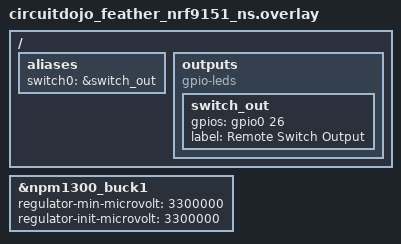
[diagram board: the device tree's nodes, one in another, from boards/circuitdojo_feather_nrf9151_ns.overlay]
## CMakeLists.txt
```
# SPDX-License-Identifier: MIT

cmake_minimum_required(VERSION 3.21.0)

# Merge the git-ignored remote-control key (README "Setup") into the
# application configuration when present. Zephyr combines this with the
# sysbuild-provided EXTRA_CONF_FILE (sysbuild/remote_switch.conf).
# CONFIGURE_DEPENDS makes Ninja re-run CMake if the key file is created or
# deleted after an initial build.
set(REMOTE_SWITCH_LOCAL_CONF ${CMAKE_CURRENT_LIST_DIR}/remote_switch.local.conf)
file(GLOB REMOTE_SWITCH_LOCAL_CONF_MATCH CONFIGURE_DEPENDS "${REMOTE_SWITCH_LOCAL_CONF}")
if(REMOTE_SWITCH_LOCAL_CONF_MATCH)
  message(STATUS "remote_switch: using ${REMOTE_SWITCH_LOCAL_CONF}")
  list(APPEND EXTRA_CONF_FILE ${REMOTE_SWITCH_LOCAL_CONF})
else()
  message(WARNING "remote_switch: ${REMOTE_SWITCH_LOCAL_CONF} not found; "
                  "remote control will be disabled (see README \"Setup\")")
endif()

find_package(Zephyr REQUIRED HINTS $ENV{ZEPHYR_BASE})
project(remote_switch)

rust_cargo_application()
target_sources(app PRIVATE src/board_io.c src/cellular.c)
target_sources_ifdef(CONFIG_REMOTE_SWITCH_DEBUG_SHELL app PRIVATE src/remote_shell.c)
set_source_files_properties(
  src/board_io.c
  src/cellular.c
  src/remote_shell.c
  PROPERTIES COMPILE_OPTIONS "-Wall;-Wextra;-Wmissing-prototypes"
)
```

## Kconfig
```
# SPDX-License-Identifier: MIT

menu "Remote switch"

config REMOTE_SWITCH_KEY
	string "Remote command key (64 hex digits)"
	default ""
	help
	  32-byte pre-shared key, hex encoded, used to authenticate remote
	  commands and replies with HMAC-SHA256. An empty or malformed value
	  disables remote control (commands are dropped).

	  Never commit a real key. Generate one into the git-ignored file
	  `remote_switch.local.conf` with
	  `tools/rsctl.py keygen -o remote_switch.local.conf`; CMakeLists.txt
	  merges that file into the build automatically when it exists.

config REMOTE_SWITCH_CELLULAR
	bool "Remote control over cellular (LTE-M / NB-IoT)"
	default y
	depends on NRF_MODEM_LIB && LTE_LINK_CONTROL && LTE_LC_PDN_MODULE && NET_SOCKETS
	help
	  Attach to the cellular network and accept authenticated commands on a
	  UDP port. The device sends nothing while idle and one small reply per
	  authenticated command.

if REMOTE_SWITCH_CELLULAR

config REMOTE_SWITCH_UDP_PORT
	int "UDP port for remote commands"
	default 4242
	range 1 65535

config REMOTE_SWITCH_CELLULAR_STACK_SIZE
	int "Cellular thread stack size"
	default 4096

config REMOTE_SWITCH_PDN_RECOVERY_TIMEOUT
	int "Seconds without a PDN connection before forcing a re-attach"
	default 300
	range 60 86400

config REMOTE_SWITCH_CELLULAR_WATCHDOG_TIMEOUT
	int "Seconds without cellular thread progress before withholding watchdog feed"
	default 900
	range 180 3600
	depends on REMOTE_SWITCH_WATCHDOG
	help
	  Maximum interval the cellular transport thread may go without
	  recording loop progress before `switch_controller` stops feeding the
	  hardware watchdog and allows `watchdog0` to reset the SoC. Generous
	  enough to span initial modem setup and fault recovery while ensuring a
	  hung modem IPC, AT command, or socket operation cannot leave remote
	  control permanently dead.

endif # REMOTE_SWITCH_CELLULAR

config REMOTE_SWITCH_WATCHDOG
	bool "Hardware watchdog supervision from switch_controller"
	default y
	depends on WATCHDOG
	help
	  Arm the SoC hardware watchdog (`aliases::watchdog0`) and feed it from
	  the async `switch_controller` executor task (gated on cellular thread
	  liveness when enabled) so an I2C bus hang, hung modem IPC, or
	  scheduler livelock resets the SoC and returns `switch0` to OFF.

if REMOTE_SWITCH_WATCHDOG

config REMOTE_SWITCH_WATCHDOG_TIMEOUT_MS
	int "Hardware watchdog timeout in milliseconds"
	default 30000
	range 3000 600000
	help
	  SoC reset timeout for `watchdog0`. A kernel timer wakes
	  `switch_controller` every one-third of this interval to feed the
	  watchdog while idle.

endif # REMOTE_SWITCH_WATCHDOG

config REMOTE_SWITCH_DEBUG_SHELL
	bool "Debug shell on console UART (`rs msg` and raw `at` commands)"
	default n
	select SHELL
	imply AT_SHELL
	help
	  Enable the interactive UART shell with the authenticated `rs msg`
	  command and raw `at` modem access. Disabled by default so production
	  builds do not expose unauthenticated UART/AT commands or spend flash
	  and RAM on the shell subsystem. Enable for bench testing via
	  `CONFIG_REMOTE_SWITCH_DEBUG_SHELL=y` in `remote_switch.local.conf` or
	  `-Dremote_switch_CONFIG_REMOTE_SWITCH_DEBUG_SHELL=y`.

endmenu

if REMOTE_SWITCH_DEBUG_SHELL

configdefault SHELL_STACK_SIZE
	default 4096

configdefault SHELL_WILDCARD
	default n

configdefault LTE_SHELL
	default n

endif # REMOTE_SWITCH_DEBUG_SHELL

source "Kconfig.zephyr"
```

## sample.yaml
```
# SPDX-License-Identifier: MIT
---
# Note: `circuitdojo_feather_nrf9151/nrf9151/ns` is built directly via
# `west build -b circuitdojo_feather_nrf9151/nrf9151/ns --sysbuild`; upstream
# `nfed` carries a legacy HWMv1 identifier (`circuitdojo_feather_nrf9151_ns`) in
# `circuitdojo_feather_nrf9151_nrf9151_ns.yaml` that Twister skips during board
# discovery, so Twister CI validates the nRF9151 Non-Secure + TF-M + MCUboot +
# modem sysbuild flow on `nrf9151dk/nrf9151/ns`. Secure-only targets are not
# listed because the nRF91 modem library requires the non-secure build.
sample:
  name: Remote Switch
  description: Rust on Zephyr cellular remote switch controller for nRF9151 Feather
common:
  sysbuild: true
  build_only: true
  filter: CONFIG_RUST_SUPPORTED
  platform_allow:
    - nrf9151dk/nrf9151/ns
  integration_platforms:
    - nrf9151dk/nrf9151/ns
  tags:
    - gpio
    - input
    - lte
    - mcuboot
    - rust
tests:
  sample.remote_switch.build: {}
  sample.remote_switch.debug_shell:
    extra_configs:
      - CONFIG_REMOTE_SWITCH_DEBUG_SHELL=y
```

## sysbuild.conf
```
# SPDX-License-Identifier: MIT

# SECURITY NOTE: By default, MCUboot signs images with its built-in development
# key (`root-ec-p256.pem`), which is public and NOT secure for production.
# For production deployments, generate an offline ECDSA-P256 keypair, keep the
# private key outside version control, and pass:
#   -DSB_CONFIG_BOOT_SIGNATURE_KEY_FILE=\"/secure/path/to/prod-key.pem\"
SB_CONFIG_BOOTLOADER_MCUBOOT=y
```

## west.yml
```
# SPDX-License-Identifier: MIT
---
manifest:
  remotes:
    - name: circuitdojo
      url-base: https://github.com/circuitdojo
    - name: zephyrproject-rtos
      url-base: https://github.com/zephyrproject-rtos

  projects:
    - name: nfed
      remote: circuitdojo
      repo-path: nrf9160-feather-examples-and-drivers.git
      path: nfed
      # Pinned commit on branch v3.4.x for reproducible builds
      revision: 79ee909971558cbea852dd668134be6ef73adfe7
      import: true
    - name: zephyr-lang-rust
      remote: zephyrproject-rtos
      repo-path: zephyr-lang-rust.git
      path: modules/lang/rust
      revision: 6823b690ed2daf636323cbb8a10447d142752e1f

  self:
    path: remote_switch
```

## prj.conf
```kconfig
# SPDX-License-Identifier: MIT

# GPIO + debounced button input subsystem
CONFIG_GPIO=y
CONFIG_INPUT=y
CONFIG_INPUT_THREAD_STACK_SIZE=2048

# Console logging
CONFIG_LOG=y
CONFIG_LOG_PRINTK=y

# Reset rather than halting with outputs latched if a fatal fault/panic occurs,
# and supervise liveness with the hardware watchdog (`aliases::watchdog0`)
CONFIG_RESET_ON_FATAL_ERROR=y
CONFIG_WATCHDOG=y

# Rust support + Embassy executor integration
CONFIG_RUST=y
CONFIG_MAIN_STACK_SIZE=4096

# Cellular modem, LTE link control, and offloaded sockets
CONFIG_NETWORKING=y
CONFIG_NET_NATIVE=n
CONFIG_NET_SOCKETS=y
CONFIG_NET_SOCKETS_OFFLOAD=y
CONFIG_NRF_MODEM_LIB=y
CONFIG_NRF_MODEM_LIB_ON_FAULT_APPLICATION_SPECIFIC=y
CONFIG_LTE_LINK_CONTROL=y
CONFIG_LTE_LC_PDN_MODULE=y
CONFIG_LTE_NETWORK_MODE_LTE_M_NBIOT=y
CONFIG_LTE_MODE_PREFERENCE_LTE_M=y

# Default PDN: 1NCE APN (change it for other SIM providers), IPv4 only so the
# network never sends IPv6 router advertisements that would count as data.
CONFIG_LTE_LC_PDN_DEFAULTS_OVERRIDE=y
CONFIG_LTE_LC_PDN_DEFAULT_APN="iot.1nce.net"
CONFIG_LTE_LC_PDN_DEFAULT_FAM_IPV4=y
CONFIG_NET_IPV6=n

# No background traffic: the app uses no DNS, NTP, or cloud services
CONFIG_LTE_LC_DNS_FALLBACK_MODULE=n

# Remote-command replay counter persisted with settings on NVS (storage_partition)
CONFIG_FLASH=y
CONFIG_FLASH_MAP=y
CONFIG_NVS=y
CONFIG_SETTINGS=y
CONFIG_SETTINGS_NVS=y

# Note: The UART debug shell (`rs msg ...` and `at ...`) is disabled by default
# for production safety and flash/RAM savings. Enable it for local bench testing
# with `CONFIG_REMOTE_SWITCH_DEBUG_SHELL=y` in `remote_switch.local.conf` or on
# the `west build` command line.
```

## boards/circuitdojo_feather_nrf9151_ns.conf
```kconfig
# SPDX-License-Identifier: MIT

# I2C + nPM1300 PMIC LED and regulator drivers (status LED + 3.3 V VDDIO on BUCK1)
CONFIG_I2C=y
CONFIG_LED=y
CONFIG_LED_NPM13XX=y
CONFIG_REGULATOR=y
CONFIG_REGULATOR_NPM13XX=y

# Disable generic gpio-leds driver so Zephyr does not contend with Rust GpioPin
# ownership of the switch0 output node (compatible = "gpio-leds" in overlay)
CONFIG_LED_GPIO=n

# Prevent TF-M UART1 from conflicting with I2C and cluttering serial logs
CONFIG_TFM_SECURE_UART=n
CONFIG_TFM_LOG_LEVEL_SILENCE=y
```

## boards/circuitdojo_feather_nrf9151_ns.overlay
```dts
/* SPDX-License-Identifier: MIT */

/*
 * Devicetree overlay for Circuit Dojo nRF9151 Feather (non-secure).
 *
 * - Default switch output is mapped to Feather header pin D2 (P0.26), active-high.
 *   Update `&gpio0 26` (and polarity if needed) to match your relay or MOSFET
 *   driver circuit, or supply a local `*.local.overlay` via `-DDTC_OVERLAY_FILE`.
 * - nPM1300 BUCK1 (`VDDIO` / `3V3`) defaults to 2.7 V via hardware VSET resistors;
 *   `&npm1300_buck1` is configured to 3.3 V so GPIO outputs drive 3.3 V logic.
 *
 * Note: `compatible = "gpio-leds"` provides the `gpios` binding for the
 * `switch0` alias (detected via `cfg!(dt = "aliases::switch0")` in Rust and
 * `GPIO_DT_SPEC_GET(DT_ALIAS(switch0), gpios)` in `src/board_io.c`), while
 * `CONFIG_LED_GPIO=n` in `boards/circuitdojo_feather_nrf9151_ns.conf` prevents
 * Zephyr's C `led_gpio` driver from claiming the same pin.
 *
 * Hardware fail-safe note: SoC GPIOs are high-impedance (floating) during
 * power-on reset, MCUboot execution, TF-M startup, and early kernel boot until
 * `board_switch_early_init` (`POST_KERNEL`) configures `switch0` as an
 * inactive output. Fit an external pull-down resistor (e.g., 10 kOhm to GND
 * for active-high drivers, or pull-up to VDD for active-low drivers) on the
 * relay/MOSFET gate so the load cannot glitch ON before firmware
 * initialization completes.
 */

/ {
	aliases {
		switch0 = &switch_out;
	};

	outputs {
		compatible = "gpio-leds";
		switch_out: switch_out {
			gpios = <&gpio0 26 GPIO_ACTIVE_HIGH>;
			label = "Remote Switch Output";
		};
	};
};

&npm1300_buck1 {
	regulator-min-microvolt = <3300000>;
	regulator-init-microvolt = <3300000>;
};
```

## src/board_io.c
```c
// SPDX-License-Identifier: MIT
/*
 * Thin C bridge for Zephyr/Nordic subsystems not yet wrapped in (or whose error
 * codes are discarded by) zephyr-lang-rust:
 *   1. Checked `aliases::switch0` GPIO output with early POST_KERNEL safe OFF.
 *   2. Onboard nPM1300 status LED (channel 2, host-controlled blue LED).
 *   3. Debounced button events via Zephyr's gpio-keys input subsystem.
 *   4. Hardware watchdog (`aliases::watchdog0`) + periodic tick timer.
 *   5. MCUboot runtime image confirmation after safe application startup.
 *   6. Flash persistence of the remote-command replay counter (settings/NVS).
 */

#include "board_io.h"

#include <errno.h>
#include <stdbool.h>
#include <stdint.h>

#include <zephyr/device.h>
#include <zephyr/devicetree.h>
#include <zephyr/init.h>
#include <zephyr/kernel.h>
#include <zephyr/logging/log.h>
#include <zephyr/sys/util.h>

#if IS_ENABLED(CONFIG_GPIO)
#include <zephyr/drivers/gpio.h>
#endif

#if IS_ENABLED(CONFIG_LED)
#include <zephyr/drivers/led.h>
#endif

#if IS_ENABLED(CONFIG_INPUT)
#include <zephyr/input/input.h>
#endif

#if IS_ENABLED(CONFIG_MCUBOOT_IMG_MANAGER)
#include <zephyr/dfu/mcuboot.h>
#endif

#if IS_ENABLED(CONFIG_REMOTE_SWITCH_WATCHDOG)
#include <zephyr/drivers/watchdog.h>
#endif

#if IS_ENABLED(CONFIG_SETTINGS)
#include <zephyr/settings/settings.h>
#endif

LOG_MODULE_REGISTER(board_io, LOG_LEVEL_INF);

#define HAS_SWITCH0_GPIO                                                                           \
	(DT_NODE_HAS_STATUS_OKAY(DT_ALIAS(switch0)) &&                                             \
	 DT_NODE_HAS_PROP(DT_ALIAS(switch0), gpios) && IS_ENABLED(CONFIG_GPIO))

#define HAS_NPM1300_STATUS_LED                                                                     \
	(DT_NODE_HAS_STATUS_OKAY(DT_NODELABEL(npm1300_leds)) && IS_ENABLED(CONFIG_LED))

#define HAS_SW0_INPUT                                                                              \
	(DT_NODE_HAS_STATUS_OKAY(DT_ALIAS(sw0)) &&                                                 \
	 DT_NODE_HAS_STATUS_OKAY(DT_PARENT(DT_ALIAS(sw0))) &&                                      \
	 DT_NODE_HAS_PROP(DT_ALIAS(sw0), zephyr_code) && IS_ENABLED(CONFIG_INPUT))

#define HAS_WATCHDOG0                                                                              \
	(DT_NODE_HAS_STATUS_OKAY(DT_ALIAS(watchdog0)) && IS_ENABLED(CONFIG_REMOTE_SWITCH_WATCHDOG))

#if HAS_SWITCH0_GPIO
static const struct gpio_dt_spec switch0_gpio = GPIO_DT_SPEC_GET(DT_ALIAS(switch0), gpios);
static atomic_t switch0_ready;

static bool configure_switch0_inactive(void)
{
	int err;

	if (!gpio_is_ready_dt(&switch0_gpio)) {
		LOG_ERR("Switch GPIO controller not ready");
		return false;
	}
	err = gpio_pin_configure_dt(&switch0_gpio, GPIO_OUTPUT_INACTIVE);
	if (err < 0) {
		LOG_ERR("Failed to configure switch0 inactive: %d", err);
		return false;
	}
	atomic_set(&switch0_ready, 1);
	return true;
}

/*
 * Drive `switch0` inactive during POST_KERNEL initialization so the pin does
 * not stay high-impedance while APPLICATION-level board hooks (such as nfed's
 * 2 s regulator settle sleep) execute before `rust_main`.
 */
static int board_switch_early_init(void)
{
	return configure_switch0_inactive() ? 0 : -EIO;
}

SYS_INIT(board_switch_early_init, POST_KERNEL, CONFIG_APPLICATION_INIT_PRIORITY);
#endif /* HAS_SWITCH0_GPIO */

bool board_switch_init(void)
{
	if (k_is_in_isr()) {
		LOG_ERR("%s cannot be called from ISR context", __func__);
		return false;
	}

#if HAS_SWITCH0_GPIO
	if (atomic_get(&switch0_ready)) {
		int err = gpio_pin_set_dt(&switch0_gpio, 0);

		if (err == 0) {
			return true;
		}
		LOG_ERR("Failed to hold switch0 inactive: %d", err);
		atomic_set(&switch0_ready, 0);
		return false;
	}
	return configure_switch0_inactive();
#else
	LOG_WRN("Devicetree alias `switch0` is not defined");
	return false;
#endif
}

int board_switch_set(bool on)
{
	if (k_is_in_isr()) {
		LOG_ERR("%s cannot be called from ISR context", __func__);
		return -EWOULDBLOCK;
	}

#if HAS_SWITCH0_GPIO
	int err;

	if (!atomic_get(&switch0_ready)) {
		return -ENODEV;
	}
	err = gpio_pin_set_dt(&switch0_gpio, on ? 1 : 0);
	if (err < 0) {
		LOG_ERR("Failed to drive switch0 %s: %d", on ? "ON" : "OFF", err);
		(void)gpio_pin_configure_dt(&switch0_gpio, GPIO_DISCONNECTED);
		atomic_set(&switch0_ready, 0);
	}
	return err;
#else
	ARG_UNUSED(on);
	return -ENOTSUP;
#endif
}

#if HAS_NPM1300_STATUS_LED
#define NPM1300_HOST_LED_CHANNEL 2U
static const struct device *const status_leds = DEVICE_DT_GET(DT_NODELABEL(npm1300_leds));
#endif

void board_status_led_set(bool on)
{
	if (k_is_in_isr()) {
		LOG_ERR("%s cannot be called from ISR context", __func__);
		return;
	}

#if HAS_NPM1300_STATUS_LED
	int err;

	if (!device_is_ready(status_leds)) {
		LOG_WRN("nPM1300 LED device not ready");
		return;
	}

	err = on ? led_on(status_leds, NPM1300_HOST_LED_CHANNEL)
		 : led_off(status_leds, NPM1300_HOST_LED_CHANNEL);
	if (err < 0) {
		LOG_WRN("Failed to update status LED: %d", err);
	}
#else
	ARG_UNUSED(on);
#endif
}

void board_confirm_image(void)
{
	if (k_is_in_isr()) {
		LOG_ERR("%s cannot be called from ISR context", __func__);
		return;
	}

#if IS_ENABLED(CONFIG_MCUBOOT_IMG_MANAGER)
	if (!boot_is_img_confirmed()) {
		int err = boot_write_img_confirmed();

		if (err < 0) {
			LOG_ERR("Failed to confirm MCUboot image: %d", err);
		} else {
			LOG_INF("MCUboot application image confirmed");
		}
	}
#endif
}

#if HAS_WATCHDOG0
static const struct device *const watchdog_dev = DEVICE_DT_GET(DT_ALIAS(watchdog0));
static int watchdog_channel = -1;
static atomic_t watchdog_started;

static void on_watchdog_timer(struct k_timer *timer)
{
	ARG_UNUSED(timer);
	rust_on_watchdog_tick();
}

static K_TIMER_DEFINE(watchdog_timer, on_watchdog_timer, NULL);

int board_watchdog_start(void)
{
	const struct wdt_timeout_cfg cfg = {
		.window =
			{
				.min = 0U,
				.max = CONFIG_REMOTE_SWITCH_WATCHDOG_TIMEOUT_MS,
			},
		.callback = NULL,
		.flags = WDT_FLAG_RESET_SOC,
	};
	const k_timeout_t feed_period = K_MSEC(CONFIG_REMOTE_SWITCH_WATCHDOG_TIMEOUT_MS / 3);
	int channel;
	int err;

	if (k_is_in_isr()) {
		LOG_ERR("%s cannot be called from ISR context", __func__);
		return -EWOULDBLOCK;
	}
	if (!atomic_cas(&watchdog_started, 0, 1)) {
		return -EALREADY;
	}
	if (!device_is_ready(watchdog_dev)) {
		LOG_ERR("Watchdog device not ready");
		atomic_set(&watchdog_started, 0);
		return -ENODEV;
	}

	channel = wdt_install_timeout(watchdog_dev, &cfg);
	if (channel < 0) {
		LOG_ERR("Failed to install watchdog timeout: %d", channel);
		atomic_set(&watchdog_started, 0);
		return channel;
	}
	err = wdt_setup(watchdog_dev, WDT_OPT_PAUSE_HALTED_BY_DBG);
	if (err < 0) {
		LOG_ERR("Failed to start watchdog: %d", err);
		atomic_set(&watchdog_started, 0);
		return err;
	}

	watchdog_channel = channel;
	(void)wdt_feed(watchdog_dev, watchdog_channel);
	k_timer_start(&watchdog_timer, feed_period, feed_period);
	LOG_INF("Hardware watchdog active (%d ms timeout)",
		CONFIG_REMOTE_SWITCH_WATCHDOG_TIMEOUT_MS);
	return 0;
}

void board_watchdog_feed(void)
{
	if (k_is_in_isr()) {
		LOG_ERR("%s cannot be called from ISR context", __func__);
		return;
	}
	if (watchdog_channel >= 0) {
		int err = wdt_feed(watchdog_dev, watchdog_channel);

		if (err < 0) {
			LOG_WRN("Failed to feed watchdog: %d", err);
		}
	}
}
#else
int board_watchdog_start(void)
{
	if (k_is_in_isr()) {
		LOG_ERR("%s cannot be called from ISR context", __func__);
		return -EWOULDBLOCK;
	}
	return 0;
}

void board_watchdog_feed(void)
{
}
#endif /* HAS_WATCHDOG0 */

#if IS_ENABLED(CONFIG_SETTINGS)
#define COUNTER_SETTINGS_KEY "remote_switch/ctr"

/* Serializes flash writes and guards `stored_counter`/`settings_ready`. */
static K_MUTEX_DEFINE(counter_lock);
static uint64_t stored_counter;
static bool settings_ready;

static int counter_settings_init_locked(void)
{
	if (!settings_ready) {
		int err = settings_subsys_init();

		if (err) {
			LOG_ERR("Settings init failed: %d", err);
			return err;
		}
		settings_ready = true;
	}
	return 0;
}

static int counter_load_cb(const char *key, size_t len, settings_read_cb read_cb, void *cb_arg,
			   void *param)
{
	uint64_t *out = param;

	/* Only accept the exact key (no sub-keys) with the expected size. */
	if ((key != NULL && key[0] != '\0') || len != sizeof(*out)) {
		return 0;
	}
	return read_cb(cb_arg, out, sizeof(*out)) == sizeof(*out) ? 1 : 0;
}

bool board_counter_load(uint64_t *value)
{
	uint64_t loaded = 0;
	bool found = false;

	if (value == NULL || k_is_in_isr()) {
		return false;
	}

	k_mutex_lock(&counter_lock, K_FOREVER);
	if (counter_settings_init_locked() == 0 &&
	    settings_load_subtree_direct(COUNTER_SETTINGS_KEY, counter_load_cb, &loaded) == 0 &&
	    loaded != 0) {
		stored_counter = MAX(stored_counter, loaded);
		*value = loaded;
		found = true;
	}
	k_mutex_unlock(&counter_lock);
	return found;
}

int board_counter_store(uint64_t value)
{
	int err;

	if (k_is_in_isr()) {
		return -EWOULDBLOCK;
	}

	k_mutex_lock(&counter_lock, K_FOREVER);
	err = counter_settings_init_locked();
	if (err == 0 && value > stored_counter) {
		err = settings_save_one(COUNTER_SETTINGS_KEY, &value, sizeof(value));
		if (err == 0) {
			stored_counter = value;
		} else {
			LOG_ERR("Failed to store replay counter: %d", err);
		}
	}
	k_mutex_unlock(&counter_lock);
	return err;
}
#else
bool board_counter_load(uint64_t *value)
{
	ARG_UNUSED(value);
	return false;
}

int board_counter_store(uint64_t value)
{
	ARG_UNUSED(value);
	return -ENOTSUP;
}
#endif /* CONFIG_SETTINGS */

#if HAS_SW0_INPUT
static void on_button_input(struct input_event *evt, void *user_data)
{
	ARG_UNUSED(user_data);

	if (evt->type == INPUT_EV_KEY && evt->code == DT_PROP(DT_ALIAS(sw0), zephyr_code) &&
	    evt->value == 1) {
		(void)rust_on_local_button_press();
	}
}

INPUT_CALLBACK_DEFINE(DEVICE_DT_GET(DT_PARENT(DT_ALIAS(sw0))), on_button_input, NULL);
#endif
```

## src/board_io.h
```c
/* SPDX-License-Identifier: MIT */
/*
 * C/Rust FFI boundary declarations for the switch GPIO output, status LED,
 * local button input, hardware watchdog, MCUboot image confirmation,
 * replay-counter storage, and the authenticated remote message handler.
 */

#ifndef REMOTE_SWITCH_BOARD_IO_H_
#define REMOTE_SWITCH_BOARD_IO_H_

#include <stdbool.h>
#include <stddef.h>
#include <stdint.h>

#ifdef __cplusplus
extern "C" {
#endif

/**
 * Maximum length of a remote message or reply in bytes. Must match
 * `protocol::MAX_MESSAGE_LEN` in `src/protocol.rs`.
 */
#define REMOTE_MESSAGE_MAX_LEN 64

/**
 * @brief Initialize (or verify early-boot initialization of) `aliases::switch0`
 *        in its safe inactive (OFF) state.
 *
 * Thread context only. Checks both GPIO controller readiness and the driver
 * return code from configuring/driving the pin inactive.
 *
 * @return true if `switch0` is present and driven inactive, false otherwise.
 */
bool board_switch_init(void);

/**
 * @brief Drive the `aliases::switch0` output active (ON) or inactive (OFF).
 *
 * Thread context only. If the GPIO driver rejects the write, `switch0` is
 * reconfigured as `GPIO_DISCONNECTED` (so the external pull resistor can return
 * the load to its safe inactive state) and marked unavailable.
 *
 * @param on true to drive active (ON), false to drive inactive (OFF).
 * @return 0 on success, negative errno on failure or when unavailable.
 */
int board_switch_set(bool on);

/**
 * @brief Update the onboard host-controlled status LED.
 *
 * Must be called from thread context only because the underlying PMIC LED
 * driver communicates over blocking I2C. Calls from ISR context are rejected
 * safely without touching the bus.
 *
 * @param on true to turn the status LED on, false to turn it off.
 */
void board_status_led_set(bool on);

/**
 * @brief Mark the running MCUboot slot image as confirmed if unconfirmed.
 *
 * Must be called from thread context after application initialization has
 * placed the switch output into its known-safe state. Safe no-op when
 * CONFIG_MCUBOOT_IMG_MANAGER is disabled or the image is already confirmed.
 */
void board_confirm_image(void);

/**
 * @brief Arm `aliases::watchdog0` and start the periodic tick timer that wakes
 *        `switch_controller` via `rust_on_watchdog_tick()`.
 *
 * Thread context only. Safe no-op returning 0 when
 * `CONFIG_REMOTE_SWITCH_WATCHDOG` is disabled or `watchdog0` is absent.
 *
 * @return 0 on success, negative errno on failure.
 */
int board_watchdog_start(void);

/**
 * @brief Feed the hardware watchdog channel armed by `board_watchdog_start()`.
 *
 * Thread context only (called from `switch_controller` on the executor thread).
 */
void board_watchdog_feed(void);

/**
 * @brief Load the last accepted remote-command counter from flash.
 *
 * Thread context only. Initializes the settings subsystem on first use.
 *
 * @param value Receives the stored counter.
 * @return true if a counter was found, false if none is stored or storage is
 *         unavailable (value is left untouched).
 */
bool board_counter_load(uint64_t *value);

/**
 * @brief Persist the last accepted remote-command counter to flash.
 *
 * Thread context only. Writes are serialized and monotonic: values that are not
 * larger than the last stored counter are ignored, so concurrent transports can
 * never move the stored counter backwards.
 *
 * @param value Counter to store.
 * @return 0 on success (or when value is not newer), negative errno otherwise.
 */
int board_counter_store(uint64_t value);

/**
 * @brief Enqueue a local toggle command from the debounced button callback.
 *
 * Lock-free, heap-allocation-free, and safe to invoke from thread or ISR
 * context.
 *
 * @return true if enqueued, false if dropped because the command queue is full.
 */
bool rust_on_local_button_press(void);

/**
 * @brief Wake `switch_controller` from the periodic watchdog timer ISR so the
 *        executor task feeds the hardware watchdog.
 *
 * Lock-free, heap-allocation-free, and safe to invoke from ISR context.
 */
void rust_on_watchdog_tick(void);

/**
 * @brief Authenticate and apply one remote message from any transport.
 *
 * The message must be an authenticated request ("<cmd> <counter> <tag>", see
 * `src/protocol.rs`). Unauthenticated, malformed, or oversized messages are
 * rejected and produce no reply, so transports must stay silent when this
 * returns 0. Thread context only (may write the replay counter to flash).
 *
 * @param message Received bytes (not NUL-terminated).
 * @param message_len Number of received bytes.
 * @param reply Buffer for the authenticated reply.
 * @param reply_capacity Size of @p reply; REMOTE_MESSAGE_MAX_LEN is enough.
 * @return Number of reply bytes to send back to the sender, or 0 to drop.
 */
int rust_handle_remote_message(const uint8_t *message, size_t message_len, uint8_t *reply,
			       size_t reply_capacity);

#ifdef __cplusplus
}
#endif

#endif /* REMOTE_SWITCH_BOARD_IO_H_ */
```

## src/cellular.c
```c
// SPDX-License-Identifier: MIT
/*
 * Cellular (LTE-M / NB-IoT) transport for authenticated remote commands.
 *
 * Data-usage policy (the SIM has a small data allowance):
 *   - The device never starts traffic. It attaches with an IPv4-only PDN (so
 *     there are no IPv6 router advertisements), resolves no hostnames, and sends
 *     no keep-alives, heartbeats, or NTP requests.
 *   - It listens on a UDP port. Commands reach it over the carrier's private
 *     network (for 1NCE, the OpenVPN service or the 1NCE API), so it needs no
 *     NAT keep-alive traffic to stay reachable.
 *   - It sends one small reply datagram per fresh authenticated request (plus a
 *     bounded retry budget for duplicate/stale requests), and drops
 *     unauthenticated or rate-limited datagrams without replying, so probes and
 *     replayed captures cannot make it spend unbounded data.
 *   - PSM and eDRX are disabled so downlink commands arrive within seconds. This
 *     costs power but no data; the board is expected to be mains powered.
 *   - Modem byte counters (AT%XCONNSTAT) are logged so data usage can be
 *     audited on the serial console.
 */

#include "cellular.h"

#include <errno.h>
#include <stdbool.h>
#include <stdint.h>

#include <zephyr/kernel.h>
#include <zephyr/sys/util.h>

#if IS_ENABLED(CONFIG_REMOTE_SWITCH_CELLULAR)

#include "board_io.h"

#include <inttypes.h>

#include <modem/lte_lc.h>
#include <modem/nrf_modem_lib.h>
#include <nrf_modem.h>
#include <nrf_modem_at.h>
#include <zephyr/logging/log.h>
#include <zephyr/net/socket.h>

LOG_MODULE_REGISTER(cellular, LOG_LEVEL_INF);

/* One extra byte detects (and drops) oversized datagrams. */
#define RX_BUF_LEN            (REMOTE_MESSAGE_MAX_LEN + 1)
#define POLL_TIMEOUT_MS       (60 * MSEC_PER_SEC)
#define PDN_WAIT_SLICE_MS     ((int64_t)POLL_TIMEOUT_MS)
#define USAGE_LOG_INTERVAL_MS (6 * 60 * 60 * MSEC_PER_SEC)
#define INIT_RETRY_DELAY      K_SECONDS(30)
#define SOCKET_RETRY_DELAY    K_SECONDS(5)

K_THREAD_STACK_DEFINE(cellular_stack, CONFIG_REMOTE_SWITCH_CELLULAR_STACK_SIZE);
static struct k_thread cellular_thread;
static atomic_t started;
static atomic_t last_heartbeat_sec;

/* Default PDN (CID 0) state and modem fault flag, safe across ISR and thread contexts. */
static atomic_t pdn_active;
static atomic_t pdn_generation;
static atomic_t modem_faulted;
static K_SEM_DEFINE(pdn_changed, 0, 1);

static void record_heartbeat(void)
{
	atomic_set(&last_heartbeat_sec, (atomic_val_t)k_uptime_seconds());
}

static const char *reg_status_str(enum lte_lc_nw_reg_status status)
{
	switch (status) {
	case LTE_LC_NW_REG_NOT_REGISTERED:
		return "not registered";
	case LTE_LC_NW_REG_REGISTERED_HOME:
		return "registered (home)";
	case LTE_LC_NW_REG_SEARCHING:
		return "searching";
	case LTE_LC_NW_REG_REGISTRATION_DENIED:
		return "registration denied";
	case LTE_LC_NW_REG_REGISTERED_ROAMING:
		return "registered (roaming)";
	case LTE_LC_NW_REG_UICC_FAIL:
		return "SIM failure";
	case LTE_LC_NW_REG_NO_SUITABLE_CELL:
		return "no suitable cell";
	default:
		return "unknown";
	}
}

static void set_pdn_active(bool active)
{
	if (active) {
		atomic_inc(&pdn_generation);
	}
	atomic_set(&pdn_active, active);
	k_sem_give(&pdn_changed);
}

static void lte_handler(const struct lte_lc_evt *const evt)
{
	switch (evt->type) {
	case LTE_LC_EVT_NW_REG_STATUS:
		LOG_INF("Network: %s", reg_status_str(evt->nw_reg_status));
		break;
	case LTE_LC_EVT_LTE_MODE_UPDATE:
		if (evt->lte_mode != LTE_LC_LTE_MODE_NONE) {
			LOG_INF("Access technology: %s",
				evt->lte_mode == LTE_LC_LTE_MODE_NBIOT ? "NB-IoT" : "LTE-M");
		}
		break;
	case LTE_LC_EVT_CELL_UPDATE:
		LOG_DBG("Cell id 0x%08x, tac 0x%04x", evt->cell.id, evt->cell.tac);
		break;
	case LTE_LC_EVT_RRC_UPDATE:
		LOG_DBG("RRC %s",
			evt->rrc_mode == LTE_LC_RRC_MODE_CONNECTED ? "connected" : "idle");
		break;
	case LTE_LC_EVT_PDN:
		if (evt->pdn.cid != 0) {
			break;
		}
		switch (evt->pdn.type) {
		case LTE_LC_EVT_PDN_ACTIVATED:
			LOG_INF("PDN connection active");
			set_pdn_active(true);
			break;
		case LTE_LC_EVT_PDN_DEACTIVATED:
		case LTE_LC_EVT_PDN_NETWORK_DETACH:
			LOG_WRN("PDN connection lost");
			set_pdn_active(false);
			break;
		default:
			break;
		}
		break;
	default:
		break;
	}
}

/*
 * Runs after every modem library (re)initialization, including recovery after
 * a modem fault, so these settings always apply.
 */
NRF_MODEM_LIB_ON_INIT(remote_switch_modem_init_hook, on_modem_lib_init, NULL);
NRF_MODEM_LIB_ON_SHUTDOWN(remote_switch_modem_shutdown_hook, on_modem_lib_shutdown, NULL);

static void on_modem_lib_init(int ret, void *ctx)
{
	ARG_UNUSED(ctx);

	if (ret != 0) {
		return;
	}
	/* Stay reachable: no PSM or eDRX sleep between paging occasions. */
	if (nrf_modem_at_printf("AT+CPSMS=0") || nrf_modem_at_printf("AT+CEDRXS=0")) {
		LOG_WRN("Failed to disable PSM/eDRX");
	}
	/* Start the modem's byte counters so data usage can be audited. */
	if (nrf_modem_at_printf("AT%%XCONNSTAT=1")) {
		LOG_WRN("Failed to start connection statistics");
	}
}

static void on_modem_lib_shutdown(void *ctx)
{
	ARG_UNUSED(ctx);
	set_pdn_active(false);
}

#if IS_ENABLED(CONFIG_NRF_MODEM_LIB_ON_FAULT_APPLICATION_SPECIFIC)
void nrf_modem_fault_handler(struct nrf_modem_fault_info *fault_info)
{
	if (fault_info != NULL) {
		LOG_ERR("Modem fault 0x%" PRIx32 " (pc 0x%08" PRIx32 ")", fault_info->reason,
			fault_info->program_counter);
	} else {
		LOG_ERR("Modem fault");
	}
	atomic_set(&modem_faulted, 1);
	set_pdn_active(false);
}
#endif

static void log_data_usage(void)
{
	int sms_tx, sms_rx, kb_tx, kb_rx, pkt_max, pkt_avg;
	int ret = nrf_modem_at_scanf("AT%XCONNSTAT?", "%%XCONNSTAT: %d,%d,%d,%d,%d,%d", &sms_tx,
				     &sms_rx, &kb_tx, &kb_rx, &pkt_max, &pkt_avg);

	if (ret == 6) {
		LOG_INF("Data since boot: %d kB up, %d kB down (largest packet %d B)", kb_tx, kb_rx,
			pkt_max);
	}
}

static void log_modem_info(void)
{
	char fw[32];

	if (nrf_modem_at_scanf("AT+CGMR", "%31[^\r\n]", fw) == 1) {
		LOG_INF("Modem firmware %s", fw);
	}
}

static void log_listen_address(void)
{
	char ip[NET_INET_ADDRSTRLEN];

	if (nrf_modem_at_scanf("AT+CGPADDR=0", "+CGPADDR: %*d,\"%15[0-9.]\"", ip) == 1) {
		LOG_INF("Listening for commands on %s:%d/udp", ip, CONFIG_REMOTE_SWITCH_UDP_PORT);
	} else {
		LOG_INF("Listening for commands on UDP port %d", CONFIG_REMOTE_SWITCH_UDP_PORT);
	}
}

static int modem_setup(void)
{
	int err;

	if (atomic_cas(&modem_faulted, 1, 0) && nrf_modem_is_initialized()) {
		err = nrf_modem_lib_shutdown();
		if (err) {
			LOG_ERR("Modem library shutdown after fault failed: %d", err);
			atomic_set(&modem_faulted, 1);
			return err;
		}
	}

	if (!nrf_modem_is_initialized()) {
		err = nrf_modem_lib_init();
		if (err) {
			LOG_ERR("Modem library init failed: %d", err);
			return err;
		}
		log_modem_info();
	}

	lte_lc_register_handler(lte_handler);
	err = lte_lc_pdn_default_ctx_events_enable();
	if (err) {
		LOG_ERR("Failed to enable PDN events: %d", err);
		return err;
	}
	/* Asynchronous attach; progress is reported through lte_handler(). */
	err = lte_lc_connect_async(NULL);
	if (err) {
		LOG_ERR("Failed to start LTE connection: %d", err);
	}
	return err;
}

static void run_modem_setup(void)
{
	record_heartbeat();
	while (modem_setup() != 0) {
		k_sleep(INIT_RETRY_DELAY);
	}
	record_heartbeat();
}

static void handle_datagram(int fd, const uint8_t *msg, size_t len, const struct net_sockaddr *from,
			    net_socklen_t from_len)
{
	uint8_t reply[REMOTE_MESSAGE_MAX_LEN];
	int reply_len;

	if (len > REMOTE_MESSAGE_MAX_LEN) {
		LOG_WRN("Dropped oversized datagram");
		return;
	}
	reply_len = rust_handle_remote_message(msg, len, reply, sizeof(reply));
	if (reply_len <= 0) {
		return; /* Rejected: stay silent so probes cannot make us spend data. */
	}
	if (zsock_sendto(fd, reply, reply_len, 0, from, from_len) < 0) {
		LOG_WRN("Failed to send reply: %d", errno);
	}
	log_data_usage();
}

/*
 * Serves commands until the PDN connection drops, is replaced, or hits a
 * socket error. Returns true on a normal PDN state transition and false on
 * socket creation/bind/poll/receive failure so the caller can back off.
 */
static bool serve_udp(void)
{
	const atomic_val_t generation = atomic_get(&pdn_generation);
	struct net_sockaddr_in local = {
		.sin_family = NET_AF_INET,
		.sin_port = net_htons(CONFIG_REMOTE_SWITCH_UDP_PORT),
		.sin_addr.s_addr = NET_INADDR_ANY,
	};
	int64_t last_usage_log = k_uptime_get();
	uint8_t rx[RX_BUF_LEN];
	bool clean_exit = false;
	int fd;

	fd = zsock_socket(NET_AF_INET, NET_SOCK_DGRAM, NET_IPPROTO_UDP);
	if (fd < 0) {
		LOG_ERR("Failed to create socket: %d", errno);
		return false;
	}
	if (zsock_bind(fd, (struct net_sockaddr *)&local, sizeof(local)) < 0) {
		LOG_ERR("Failed to bind UDP port %d: %d", CONFIG_REMOTE_SWITCH_UDP_PORT, errno);
		goto out;
	}
	log_listen_address();

	while (atomic_get(&pdn_active) && !atomic_get(&modem_faulted) &&
	       atomic_get(&pdn_generation) == generation) {
		struct zsock_pollfd pfd = {.fd = fd, .events = ZSOCK_POLLIN};
		struct net_sockaddr_storage from;
		net_socklen_t from_len = sizeof(from);
		ssize_t len;
		int ret = zsock_poll(&pfd, 1, POLL_TIMEOUT_MS);

		if (!atomic_get(&modem_faulted) &&
		    k_uptime_get() - last_usage_log >= USAGE_LOG_INTERVAL_MS) {
			last_usage_log = k_uptime_get();
			log_data_usage();
		}
		if (ret == 0) {
			record_heartbeat();
			continue; /* Timeout: re-check the PDN state. */
		}
		if (ret < 0 || (pfd.revents & (ZSOCK_POLLERR | ZSOCK_POLLHUP | ZSOCK_POLLNVAL))) {
			LOG_WRN("Socket error (poll %d, revents 0x%x, errno %d)", ret, pfd.revents,
				errno);
			goto out;
		}

		len = zsock_recvfrom(fd, rx, sizeof(rx), ZSOCK_MSG_DONTWAIT,
				     (struct net_sockaddr *)&from, &from_len);
		if (len < 0) {
			if (errno == EAGAIN || errno == EWOULDBLOCK) {
				record_heartbeat();
				continue;
			}
			LOG_WRN("recvfrom failed: %d", errno);
			goto out;
		}
		handle_datagram(fd, rx, len, (struct net_sockaddr *)&from, from_len);
		record_heartbeat();
	}
	clean_exit = true;
out:
	zsock_close(fd);
	return clean_exit;
}

static void cellular_thread_fn(void *p1, void *p2, void *p3)
{
	const int64_t recovery_ms =
		(int64_t)CONFIG_REMOTE_SWITCH_PDN_RECOVERY_TIMEOUT * (int64_t)MSEC_PER_SEC;
	int64_t pdn_lost_since;

	ARG_UNUSED(p1);
	ARG_UNUSED(p2);
	ARG_UNUSED(p3);

	run_modem_setup();
	pdn_lost_since = k_uptime_get();

	for (;;) {
		int64_t remaining_ms;

		if (atomic_get(&modem_faulted)) {
			LOG_WRN("Re-initializing modem after fault");
			run_modem_setup();
			pdn_lost_since = k_uptime_get();
			continue;
		}
		if (atomic_get(&pdn_active)) {
			if (serve_udp()) {
				pdn_lost_since = k_uptime_get();
			} else if (atomic_get(&pdn_active) && !atomic_get(&modem_faulted)) {
				k_sleep(SOCKET_RETRY_DELAY);
			} else {
				pdn_lost_since = k_uptime_get();
			}
			continue;
		}

		remaining_ms = recovery_ms - (k_uptime_get() - pdn_lost_since);
		if (remaining_ms > 0) {
			int64_t wait_ms = MIN(remaining_ms, PDN_WAIT_SLICE_MS);

			record_heartbeat();
			(void)k_sem_take(&pdn_changed, K_MSEC(wait_ms));
			continue;
		}

		/* Re-attach in case the modem was reset or got stuck searching. */
		LOG_WRN("No PDN connection for %d s; re-attaching",
			CONFIG_REMOTE_SWITCH_PDN_RECOVERY_TIMEOUT);
		if (lte_lc_offline() != 0 || lte_lc_normal() != 0) {
			LOG_WRN("PDN recovery AT command failed; re-initializing modem");
			atomic_set(&modem_faulted, 1);
		} else {
			record_heartbeat();
		}
		pdn_lost_since = k_uptime_get();
	}
}

int cellular_start(void)
{
	if (!atomic_cas(&started, 0, 1)) {
		return -EALREADY;
	}
	record_heartbeat();
	k_thread_create(&cellular_thread, cellular_stack, K_THREAD_STACK_SIZEOF(cellular_stack),
			cellular_thread_fn, NULL, NULL, NULL, K_PRIO_PREEMPT(7), 0, K_NO_WAIT);
	k_thread_name_set(&cellular_thread, "cellular");
	return 0;
}

bool cellular_is_healthy(void)
{
#if IS_ENABLED(CONFIG_REMOTE_SWITCH_WATCHDOG)
	uint32_t elapsed;

	if (!atomic_get(&started)) {
		return true;
	}
	elapsed = k_uptime_seconds() - (uint32_t)atomic_get(&last_heartbeat_sec);
	return elapsed <= (uint32_t)CONFIG_REMOTE_SWITCH_CELLULAR_WATCHDOG_TIMEOUT;
#else
	return true;
#endif
}

#else /* !CONFIG_REMOTE_SWITCH_CELLULAR */

int cellular_start(void)
{
	return -ENOTSUP;
}

bool cellular_is_healthy(void)
{
	return true;
}

#endif /* CONFIG_REMOTE_SWITCH_CELLULAR */
```

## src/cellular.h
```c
/* SPDX-License-Identifier: MIT */
/*
 * Cellular (LTE-M / NB-IoT) transport for authenticated remote commands.
 */

#ifndef REMOTE_SWITCH_CELLULAR_H_
#define REMOTE_SWITCH_CELLULAR_H_

#include <stdbool.h>

#ifdef __cplusplus
extern "C" {
#endif

/**
 * @brief Start the cellular link and the UDP command listener.
 *
 * Spawns a thread that initializes the modem, attaches to the network, and
 * serves authenticated commands on CONFIG_REMOTE_SWITCH_UDP_PORT. Returns
 * immediately. Call once from thread context after the remote key and the
 * replay counter have been initialized.
 *
 * @return 0 on success, -EALREADY if already started, or -ENOTSUP when
 *         CONFIG_REMOTE_SWITCH_CELLULAR is disabled.
 */
int cellular_start(void);

/**
 * @brief Check whether the cellular transport thread is making forward progress.
 *
 * Safe to call from any thread context. Returns true when cellular support or
 * watchdog supervision is disabled, before `cellular_start()` has been called,
 * or while the cellular thread has recorded a heartbeat within
 * `CONFIG_REMOTE_SWITCH_CELLULAR_WATCHDOG_TIMEOUT` seconds.
 *
 * @return true if healthy (or inactive), false if unresponsive.
 */
bool cellular_is_healthy(void);

#ifdef __cplusplus
}
#endif

#endif /* REMOTE_SWITCH_CELLULAR_H_ */
```

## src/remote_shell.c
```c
// SPDX-License-Identifier: MIT
/*
 * Debug shell command that feeds a remote message to the same authenticated
 * handler the UDP transport uses, so the full command path (authentication,
 * replay protection, flash persistence, actuation) can be tested over the
 * serial console without spending cellular data:
 *
 *   uart:~$ rs msg on 1761840000123 16d82a013add92ef
 *   on 1761840000123 50d3e76858638e40
 *
 * Generate messages with `tools/rsctl.py payload <on|off|status>`.
 */

#include "board_io.h"

#include <errno.h>
#include <string.h>

#include <zephyr/shell/shell.h>

static int cmd_rs_msg(const struct shell *sh, size_t argc, char **argv)
{
	uint8_t msg[REMOTE_MESSAGE_MAX_LEN];
	uint8_t reply[REMOTE_MESSAGE_MAX_LEN];
	size_t len = 0;
	int reply_len;

	/* Re-join the shell arguments into one space-separated message. */
	for (size_t i = 1; i < argc; i++) {
		size_t arg_len = strlen(argv[i]);

		if (len + (i > 1 ? 1 : 0) + arg_len > REMOTE_MESSAGE_MAX_LEN) {
			shell_error(sh, "Message longer than %d bytes", REMOTE_MESSAGE_MAX_LEN);
			return -EINVAL;
		}
		if (i > 1) {
			msg[len++] = ' ';
		}
		memcpy(&msg[len], argv[i], arg_len);
		len += arg_len;
	}

	reply_len = rust_handle_remote_message(msg, len, reply, sizeof(reply));
	if (reply_len <= 0) {
		shell_warn(sh, "Dropped (unauthenticated, malformed, or remote control disabled)");
		return -EACCES;
	}
	shell_print(sh, "%.*s", reply_len, (const char *)reply);
	return 0;
}

SHELL_STATIC_SUBCMD_SET_CREATE(rs_cmds,
			       SHELL_CMD_ARG(msg, NULL,
					     "Handle a remote message: msg <cmd> <counter> <tag>",
					     cmd_rs_msg, 4, 0),
			       SHELL_SUBCMD_SET_END);

SHELL_CMD_REGISTER(rs, &rs_cmds, "Remote switch commands", NULL);
```
